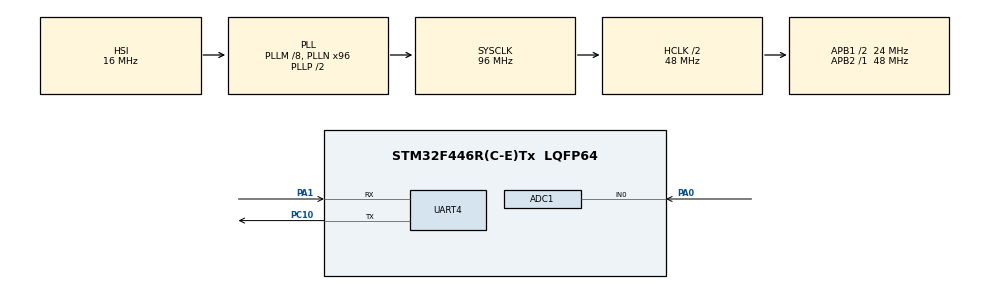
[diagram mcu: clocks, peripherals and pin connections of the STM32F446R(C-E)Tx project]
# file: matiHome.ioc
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ADC1.Channel-0\#ChannelRegularConversion=ADC_CHANNEL_0
ADC1.ContinuousConvMode=DISABLE
ADC1.DMAContinuousRequests=ENABLE
ADC1.NbrOfConversion=1
ADC1.NbrOfConversionFlag=1
ADC1.Rank-0\#ChannelRegularConversion=1
ADC1.SamplingTime-0\#ChannelRegularConversion=ADC_SAMPLETIME_3CYCLES
ADC1.master=1
Dma.ADC1.0.Direction=DMA_PERIPH_TO_MEMORY
Dma.ADC1.0.FIFOMode=DMA_FIFOMODE_DISABLE
Dma.ADC1.0.Instance=DMA2_Stream0
Dma.ADC1.0.MemDataAlignment=DMA_MDATAALIGN_HALFWORD
Dma.ADC1.0.MemInc=DMA_MINC_ENABLE
Dma.ADC1.0.Mode=DMA_CIRCULAR
Dma.ADC1.0.PeriphDataAlignment=DMA_PDATAALIGN_HALFWORD
Dma.ADC1.0.PeriphInc=DMA_PINC_DISABLE
Dma.ADC1.0.Priority=DMA_PRIORITY_HIGH
Dma.Request0=ADC1
Mcu.Family=STM32F4
Mcu.Name=STM32F446R(C-E)Tx
Mcu.Package=LQFP64
NVIC.DMA2_Stream0_IRQn=true\:0\:0\:false\:false\:true\:false\:true
NVIC.PriorityGroup=NVIC_PRIORITYGROUP_4
NVIC.TIM7_IRQn=true\:0\:0\:false\:false\:true\:true\:true
NVIC.UART4_IRQn=true\:0\:0\:false\:false\:true\:true\:true
PA0-WKUP.Signal=ADCx_IN0
PA1.Mode=Asynchronous
PA1.Signal=UART4_RX
PC10.Mode=Asynchronous
PC10.Signal=UART4_TX
ProjectManager.HeapSize=0x200
ProjectManager.StackSize=0x400
ProjectManager.TargetToolchain=STM32CubeIDE
RCC.AHBCLKDivider=RCC_SYSCLK_DIV2
RCC.AHBFreq_Value=48000000
RCC.APB1CLKDivider=RCC_HCLK_DIV2
RCC.APB1Freq_Value=24000000
RCC.APB1TimFreq_Value=48000000
RCC.APB2Freq_Value=48000000
RCC.APB2TimFreq_Value=48000000
RCC.CortexFreq_Value=48000000
RCC.HCLKFreq_Value=48000000
RCC.PLLM=8
RCC.PLLN=96
RCC.SYSCLKFreq_VALUE=96000000
RCC.SYSCLKSource=RCC_SYSCLKSOURCE_PLLCLK
RCC.USBFreq_Value=96000000
RCC.VCOOutputFreq_Value=192000000
SH.ADCx_IN0.0=ADC1_IN0,IN0
TIM7.Period=999
TIM7.Prescaler=5
UART4.VirtualMode=Asynchronous
VP_TIM7_VS_ClockSourceINT.Mode=Enable_Timer
board=custom

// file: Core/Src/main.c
/* USER CODE BEGIN Header */
/**
  ******************************************************************************
  * @file           : main.c
  * @brief          : Main program body
  ******************************************************************************
  * @attention
  *
  * <h2><center>&copy; Copyright (c) 2021 STMicroelectronics.
  * All rights reserved.</center></h2>
  *
  * This software component is licensed by ST under BSD 3-Clause license,
  * the "License"; You may not use this file except in compliance with the
  * License. You may obtain a copy of the License at:
  *                        opensource.org/licenses/BSD-3-Clause
  *
  ******************************************************************************
  */
/* USER CODE END Header */
#include "main.h"

/* USER CODE BEGIN Includes */
#include "bt_command_send.h"
#include "bt_command_decode2.h"
#include "uart.h"
#include <stdio.h>
#include "DTMF.h"

/* USER CODE END Includes */

ADC_HandleTypeDef hadc1;
DMA_HandleTypeDef hdma_adc1;

TIM_HandleTypeDef htim7;

UART_HandleTypeDef huart4;

/* USER CODE BEGIN PV */
#define BUFLEN 1
#define USE_DMA
volatile uint16_t aResultDMA[BUFLEN];
static char DTMFchar[16] = {
  '1', '2', '3', 'A',
  '4', '5', '6', 'B',
  '7', '8', '9', 'C',
  '*', '0', '#', 'D',
};

/* USER CODE END PV */

void SystemClock_Config(void);
static void MX_GPIO_Init(void);
static void MX_UART4_Init(void);
static void MX_DMA_Init(void);
static void MX_ADC1_Init(void);
static void MX_TIM7_Init(void);

int main(void)
{

  /* MCU Configuration--------------------------------------------------------*/

  /* Reset of all peripherals, Initializes the Flash interface and the Systick. */
  HAL_Init();

  /* Configure the system clock */
  SystemClock_Config();

  /* Initialize all configured peripherals */
  MX_GPIO_Init();
  MX_UART4_Init();
  MX_DMA_Init();
  MX_ADC1_Init();
  MX_TIM7_Init();
  /* USER CODE BEGIN 2 */
  BT_CommandDecodeInit();
  USART_Init(&huart4);
  //BT_CallNumber("720719331", 9);
  //BT_Action(ANY_MODE_ENTERING_PAIRING);

#ifdef USE_DMA
	/* Start ADC DMA */
	if(HAL_ADC_Start_DMA(&hadc1, (uint32_t*)aResultDMA, BUFLEN) != HAL_OK)
		while(1);
#endif

	/* Start 8kHz timer */
	if(HAL_TIM_Base_Start_IT(&htim7) != HAL_OK)
		while(1);

  /* USER CODE END 2 */

  /* Infinite loop */
  /* USER CODE BEGIN WHILE */
  while (1)
  {

	  //BTAPP_EnterBTPairingMode();
	  //HAL_Delay(1);
	  BT_CommandDecodeMain();

		/* run DTMF decoder */
		if (dail1.AIindex >= dail1.AIcheck)  {
			DTMF_Detect (&dail1);
		}

		if (dail1.new){

			char klawa = DTMFchar[dail1.digit & 0x0F];
			dail1.new = 0;

		}

    /* USER CODE END WHILE */

  }
}

void SystemClock_Config(void)
{
  RCC_OscInitTypeDef RCC_OscInitStruct = {0};
  RCC_ClkInitTypeDef RCC_ClkInitStruct = {0};

  /** Configure the main internal regulator output voltage
  */
  __HAL_RCC_PWR_CLK_ENABLE();
  __HAL_PWR_VOLTAGESCALING_CONFIG(PWR_REGULATOR_VOLTAGE_SCALE3);
  /** Initializes the RCC Oscillators according to the specified parameters
  * in the RCC_OscInitTypeDef structure.
  */
  RCC_OscInitStruct.OscillatorType = RCC_OSCILLATORTYPE_HSI;
  RCC_OscInitStruct.HSIState = RCC_HSI_ON;
  RCC_OscInitStruct.HSICalibrationValue = RCC_HSICALIBRATION_DEFAULT;
  RCC_OscInitStruct.PLL.PLLState = RCC_PLL_ON;
  RCC_OscInitStruct.PLL.PLLSource = RCC_PLLSOURCE_HSI;
  RCC_OscInitStruct.PLL.PLLM = 8;
  RCC_OscInitStruct.PLL.PLLN = 96;
  RCC_OscInitStruct.PLL.PLLP = RCC_PLLP_DIV2;
  RCC_OscInitStruct.PLL.PLLQ = 2;
  RCC_OscInitStruct.PLL.PLLR = 2;
  if (HAL_RCC_OscConfig(&RCC_OscInitStruct) != HAL_OK)
  {
    Error_Handler();
  }
  /** Initializes the CPU, AHB and APB buses clocks
  */
  RCC_ClkInitStruct.ClockType = RCC_CLOCKTYPE_HCLK|RCC_CLOCKTYPE_SYSCLK
                              |RCC_CLOCKTYPE_PCLK1|RCC_CLOCKTYPE_PCLK2;
  RCC_ClkInitStruct.SYSCLKSource = RCC_SYSCLKSOURCE_PLLCLK;
  RCC_ClkInitStruct.AHBCLKDivider = RCC_SYSCLK_DIV2;
  RCC_ClkInitStruct.APB1CLKDivider = RCC_HCLK_DIV2;
  RCC_ClkInitStruct.APB2CLKDivider = RCC_HCLK_DIV1;

  if (HAL_RCC_ClockConfig(&RCC_ClkInitStruct, FLASH_LATENCY_1) != HAL_OK)
  {
    Error_Handler();
  }
}

static void MX_ADC1_Init(void)
{

  ADC_ChannelConfTypeDef sConfig = {0};

  /** Configure the global features of the ADC (Clock, Resolution, Data Alignment and number of conversion)
  */
  hadc1.Instance = ADC1;
  hadc1.Init.ClockPrescaler = ADC_CLOCK_SYNC_PCLK_DIV2;
  hadc1.Init.Resolution = ADC_RESOLUTION_12B;
  hadc1.Init.ScanConvMode = DISABLE;
  hadc1.Init.ContinuousConvMode = DISABLE;
  hadc1.Init.DiscontinuousConvMode = DISABLE;
  hadc1.Init.ExternalTrigConvEdge = ADC_EXTERNALTRIGCONVEDGE_NONE;
  hadc1.Init.ExternalTrigConv = ADC_SOFTWARE_START;
  hadc1.Init.DataAlign = ADC_DATAALIGN_RIGHT;
  hadc1.Init.NbrOfConversion = 1;
  hadc1.Init.DMAContinuousRequests = ENABLE;
  hadc1.Init.EOCSelection = ADC_EOC_SINGLE_CONV;
  if (HAL_ADC_Init(&hadc1) != HAL_OK)
  {
    Error_Handler();
  }
  /** Configure for the selected ADC regular channel its corresponding rank in the sequencer and its sample time.
  */
  sConfig.Channel = ADC_CHANNEL_0;
  sConfig.Rank = 1;
  sConfig.SamplingTime = ADC_SAMPLETIME_3CYCLES;
  if (HAL_ADC_ConfigChannel(&hadc1, &sConfig) != HAL_OK)
  {
    Error_Handler();
  }

}

static void MX_TIM7_Init(void)
{

  TIM_MasterConfigTypeDef sMasterConfig = {0};

  htim7.Instance = TIM7;
  htim7.Init.Prescaler = 5;
  htim7.Init.CounterMode = TIM_COUNTERMODE_UP;
  htim7.Init.Period = 999;
  htim7.Init.AutoReloadPreload = TIM_AUTORELOAD_PRELOAD_DISABLE;
  if (HAL_TIM_Base_Init(&htim7) != HAL_OK)
  {
    Error_Handler();
  }
  sMasterConfig.MasterOutputTrigger = TIM_TRGO_RESET;
  sMasterConfig.MasterSlaveMode = TIM_MASTERSLAVEMODE_DISABLE;
  if (HAL_TIMEx_MasterConfigSynchronization(&htim7, &sMasterConfig) != HAL_OK)
  {
    Error_Handler();
  }

}

static void MX_UART4_Init(void)
{

  huart4.Instance = UART4;
  huart4.Init.BaudRate = 115200;
  huart4.Init.WordLength = UART_WORDLENGTH_8B;
  huart4.Init.StopBits = UART_STOPBITS_1;
  huart4.Init.Parity = UART_PARITY_NONE;
  huart4.Init.Mode = UART_MODE_TX_RX;
  huart4.Init.HwFlowCtl = UART_HWCONTROL_NONE;
  huart4.Init.OverSampling = UART_OVERSAMPLING_16;
  if (HAL_UART_Init(&huart4) != HAL_OK)
  {
    Error_Handler();
  }

}

static void MX_DMA_Init(void)
{

  /* DMA controller clock enable */
  __HAL_RCC_DMA2_CLK_ENABLE();

  /* DMA interrupt init */
  /* DMA2_Stream0_IRQn interrupt configuration */
  HAL_NVIC_SetPriority(DMA2_Stream0_IRQn, 0, 0);
  HAL_NVIC_EnableIRQ(DMA2_Stream0_IRQn);

}

static void MX_GPIO_Init(void)
{

  /* GPIO Ports Clock Enable */
  __HAL_RCC_GPIOA_CLK_ENABLE();
  __HAL_RCC_GPIOC_CLK_ENABLE();

}

/* USER CODE BEGIN 4 */

void HAL_TIM_PeriodElapsedCallback(TIM_HandleTypeDef *htim)
{
	int err;

#ifdef USE_DMA
	dail1.AInput[dail1.AIindex & (DTMFsz-1)] = aResultDMA[0];
	HAL_ADC_Start_DMA(&hadc1, (uint32_t*)aResultDMA, BUFLEN);
	dail1.AIindex++;
#else

	err = HAL_ADC_Start(&hadc);
	if(err != HAL_OK)
		while(1);

	err = HAL_ADC_PollForConversion(&hadc, HAL_MAX_DELAY);

	dail1.AInput[dail1.AIindex & (DTMFsz-1)] = HAL_ADC_GetValue(&hadc);
	dail1.AIindex++;

	err = HAL_ADC_Stop(&hadc);
	if(err != HAL_OK)
		while(1);
#endif

}

/* USER CODE END 4 */

void Error_Handler(void)
{
  __disable_irq();
  while (1)
  {
  }
}

/************************ (C) COPYRIGHT STMicroelectronics *****END OF FILE****/
